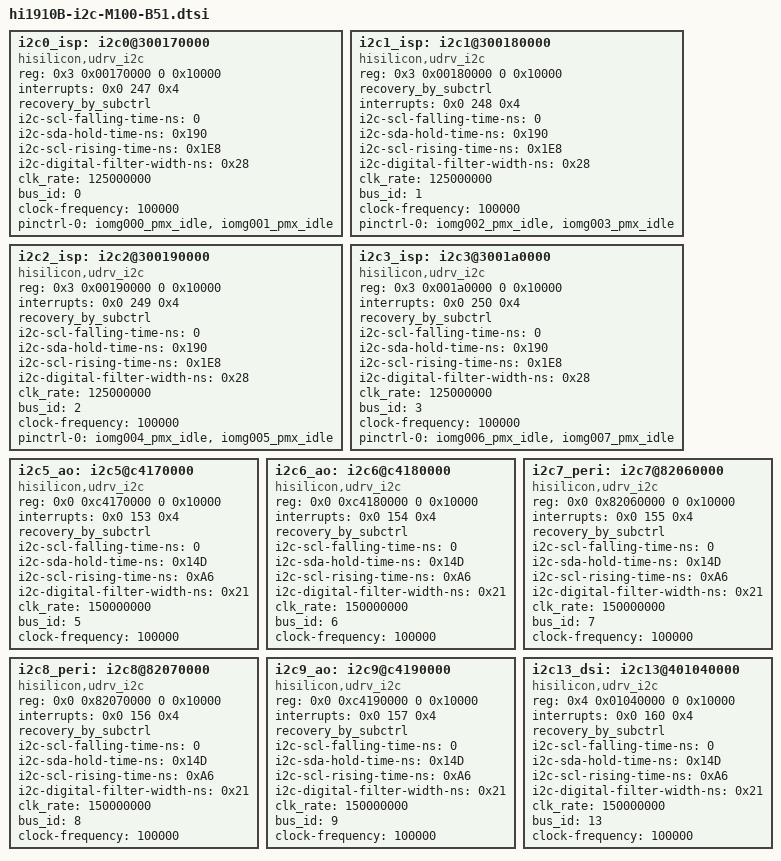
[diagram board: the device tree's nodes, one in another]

	i2c0_isp:i2c0@300170000{
		compatible = "hisilicon,udrv_i2c";
		#address-cells = <1>;
		#size-cells = <0>;
		reg = <0x3 0x00170000 0 0x10000>;
		interrupts = <0x0 247 0x4>;
		recovery_by_subctrl;
		//i2c-sda-falling-time-ns = <0>;              not used
		//i2c-scl-internal-delay-ns = <0>;            not used
		//i2c-analog-filter-cutoff-frequency = <0>;   not used
		i2c-scl-falling-time-ns = <0>;
		i2c-sda-hold-time-ns = <0x190>;
		i2c-scl-rising-time-ns = <0x1E8>;
		i2c-digital-filter-width-ns = <0x28>;
		// 125M时钟
		clk_rate = <125000000>;
		bus_id = <0>;
		// 速率100k
		clock-frequency = <100000>;
		// To enable the I2C 0, uncomment the following two lines and comment the pinctrl configuration of the SPI 3
		pinctrl-names = "default";
		pinctrl-0 = <&iomg000_pmx_idle &iomg001_pmx_idle>;
	};

	i2c1_isp:i2c1@300180000{
		compatible = "hisilicon,udrv_i2c";
		#address-cells = <1>;
		#size-cells = <0>;
		reg = <0x3 0x00180000 0 0x10000>;
		recovery_by_subctrl;
		interrupts = <0x0 248 0x4>;
		//i2c-sda-falling-time-ns = <0>;              not used
		//i2c-scl-internal-delay-ns = <0>;            not used
		//i2c-analog-filter-cutoff-frequency = <0>;   not used
		i2c-scl-falling-time-ns = <0>;
		i2c-sda-hold-time-ns = <0x190>;
		i2c-scl-rising-time-ns = <0x1E8>;
		i2c-digital-filter-width-ns = <0x28>;
		// 125M时钟
		clk_rate = <125000000>;
		bus_id = <1>;
		// 速率100k
		clock-frequency = <100000>;
		// To enable the I2C 1, uncomment the following two lines and comment the pinctrl configuration of the SPI 3
		pinctrl-names = "default";
		pinctrl-0 = <&iomg002_pmx_idle &iomg003_pmx_idle>;
	};

	i2c2_isp:i2c2@300190000{
		compatible = "hisilicon,udrv_i2c";
		#address-cells = <1>;
		#size-cells = <0>;
		reg = <0x3 0x00190000 0 0x10000>;
		interrupts = <0x0 249 0x4>;
		recovery_by_subctrl;
		//i2c-sda-falling-time-ns = <0>;              not used
		//i2c-scl-internal-delay-ns = <0>;            not used
		//i2c-analog-filter-cutoff-frequency = <0>;   not used
		i2c-scl-falling-time-ns = <0>;
		i2c-sda-hold-time-ns = <0x190>;
		i2c-scl-rising-time-ns = <0x1E8>;
		i2c-digital-filter-width-ns = <0x28>;
		// 125M时钟
		clk_rate = <125000000>;
		bus_id = <2>;
		// 速率100k
		clock-frequency = <100000>;
		// To enable the I2C 2, uncomment the following two lines and comment the pinctrl configuration of the SPI 4
		pinctrl-names = "default";
		pinctrl-0 = <&iomg004_pmx_idle &iomg005_pmx_idle>;
	};

	i2c3_isp:i2c3@3001a0000{
		compatible = "hisilicon,udrv_i2c";
		#address-cells = <1>;
		#size-cells = <0>;
		reg = <0x3 0x001a0000 0 0x10000>;
		interrupts = <0x0 250 0x4>;
		recovery_by_subctrl;
		//i2c-sda-falling-time-ns = <0>;              not used
		//i2c-scl-internal-delay-ns = <0>;            not used
		//i2c-analog-filter-cutoff-frequency = <0>;   not used
		i2c-scl-falling-time-ns = <0>;
		i2c-sda-hold-time-ns = <0x190>;
		i2c-scl-rising-time-ns = <0x1E8>;
		i2c-digital-filter-width-ns = <0x28>;
		// 125M时钟
		clk_rate = <125000000>;
		bus_id = <3>;
		// 速率100k
		clock-frequency = <100000>;
		// To enable the I2C 3, uncomment the following two lines and comment the pinctrl configuration of the SPI 4
		pinctrl-names = "default";
		pinctrl-0 = <&iomg006_pmx_idle &iomg007_pmx_idle>;
	};

	// i2c4_ao:i2c4@c4160000{
        // i2c4 is controlled by LP subsystem, not configured by hisi_i2c driver
	//};

	i2c5_ao:i2c5@c4170000{
		compatible = "hisilicon,udrv_i2c";
		#address-cells = <1>;
		#size-cells = <0>;
		reg = <0x0 0xc4170000 0 0x10000>;
		interrupts = <0x0 153 0x4>;
		recovery_by_subctrl;
		//i2c-sda-falling-time-ns = <0>;              not used
		//i2c-scl-internal-delay-ns = <0>;            not used
		//i2c-analog-filter-cutoff-frequency = <0>;   not used
		i2c-scl-falling-time-ns = <0>;
		i2c-sda-hold-time-ns = <0x14D>;
		i2c-scl-rising-time-ns = <0xA6>;
		i2c-digital-filter-width-ns = <0x21>;
		// 150M时钟
		clk_rate = <150000000>;
		bus_id = <5>;
		// 速率100k
		clock-frequency = <100000>;
	};

	i2c6_ao:i2c6@c4180000{
		compatible = "hisilicon,udrv_i2c";
		#address-cells = <1>;
		#size-cells = <0>;
		reg = <0x0 0xc4180000 0 0x10000>;
		interrupts = <0x0 154 0x4>;
		recovery_by_subctrl;
		//i2c-sda-falling-time-ns = <0>;              not used
		//i2c-scl-internal-delay-ns = <0>;            not used
		//i2c-analog-filter-cutoff-frequency = <0>;   not used
		i2c-scl-falling-time-ns = <0>;
		i2c-sda-hold-time-ns = <0x14D>;
		i2c-scl-rising-time-ns = <0xA6>;
		i2c-digital-filter-width-ns = <0x21>;
		// 150M时钟
		clk_rate = <150000000>;
		bus_id = <6>;
		// 速率100k
		clock-frequency = <100000>;
	};

	i2c7_peri:i2c7@82060000{
		compatible = "hisilicon,udrv_i2c";
		#address-cells = <1>;
		#size-cells = <0>;
		reg = <0x0 0x82060000 0 0x10000>;
		interrupts = <0x0 155 0x4>;
		recovery_by_subctrl;
		//i2c-sda-falling-time-ns = <0>;              not used
		//i2c-scl-internal-delay-ns = <0>;            not used
		//i2c-analog-filter-cutoff-frequency = <0>;   not used
		i2c-scl-falling-time-ns = <0>;
		i2c-sda-hold-time-ns = <0x14D>;
		i2c-scl-rising-time-ns = <0xA6>;
		i2c-digital-filter-width-ns = <0x21>;
		// 150M时钟
		clk_rate = <150000000>;
		bus_id = <7>;
		// 速率100k
		clock-frequency = <100000>;
	};

	i2c8_peri:i2c8@82070000{
		compatible = "hisilicon,udrv_i2c";
		#address-cells = <1>;
		#size-cells = <0>;
		reg = <0x0 0x82070000 0 0x10000>;
		interrupts = <0x0 156 0x4>;
		recovery_by_subctrl;
		//i2c-sda-falling-time-ns = <0>;              not used
		//i2c-scl-internal-delay-ns = <0>;            not used
		//i2c-analog-filter-cutoff-frequency = <0>;   not used
		i2c-scl-falling-time-ns = <0>;
		i2c-sda-hold-time-ns = <0x14D>;
		i2c-scl-rising-time-ns = <0xA6>;
		i2c-digital-filter-width-ns = <0x21>;
		// 150M时钟
		clk_rate = <150000000>;
		bus_id = <8>;
		// 速率100k
		clock-frequency = <100000>;
	};

	i2c9_ao:i2c9@c4190000{
		compatible = "hisilicon,udrv_i2c";
		#address-cells = <1>;
		#size-cells = <0>;
		reg = <0x0 0xc4190000 0 0x10000>;
		interrupts = <0x0 157 0x4>;
		recovery_by_subctrl;
		//i2c-sda-falling-time-ns = <0>;              not used
		//i2c-scl-internal-delay-ns = <0>;            not used
		//i2c-analog-filter-cutoff-frequency = <0>;   not used
		i2c-scl-falling-time-ns = <0>;
		i2c-sda-hold-time-ns = <0x14D>;
		i2c-scl-rising-time-ns = <0xA6>;
		i2c-digital-filter-width-ns = <0x21>;
		// 150M时钟
		clk_rate = <150000000>;
		bus_id = <9>;
		// 速率100k
		clock-frequency = <100000>;
	};

	i2c13_dsi:i2c13@401040000{
		compatible = "hisilicon,udrv_i2c";
		#address-cells = <1>;
		#size-cells = <0>;
		reg = <0x4 0x01040000 0 0x10000>;
		interrupts = <0x0 160 0x4>;
		recovery_by_subctrl;
		//i2c-sda-falling-time-ns = <0>;              not used
		//i2c-scl-internal-delay-ns = <0>;            not used
		//i2c-analog-filter-cutoff-frequency = <0>;   not used
		i2c-scl-falling-time-ns = <0>;
		i2c-sda-hold-time-ns = <0x14D>;
		i2c-scl-rising-time-ns = <0xA6>;
		i2c-digital-filter-width-ns = <0x21>;
		// 150M时钟
		clk_rate = <150000000>;
		bus_id = <13>;
		// 速率100k
		clock-frequency = <100000>;
	};

